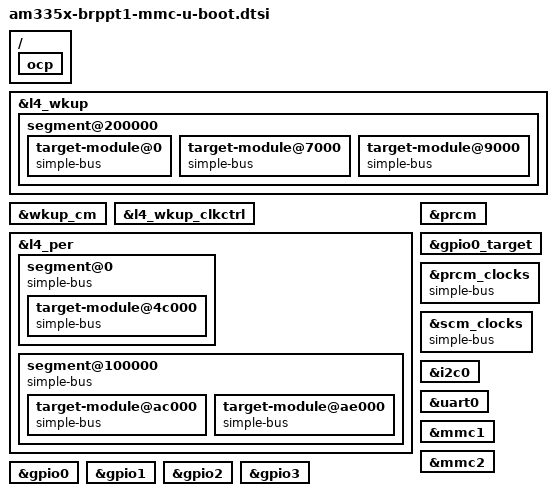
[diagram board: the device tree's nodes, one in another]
// SPDX-License-Identifier: GPL-2.0+
/*
 * Copyright (C) 2022 B&R Industrial Automation GmbH -
 * https://www.br-automation.com/
 */

/ {
	ocp {
		u-boot,dm-all;
	};
};

&l4_wkup {
	u-boot,dm-all;
	segment@200000 {
		u-boot,dm-all;
		target-module@0
		{
			u-boot,dm-all;
			compatible = "simple-bus";
		};
		target-module@7000 {
			u-boot,dm-all;
			compatible = "simple-bus";
		};
		target-module@9000 {
			u-boot,dm-all;
			compatible = "simple-bus";
		};
	};
};

&wkup_cm {
	u-boot,dm-all;
};

&l4_wkup_clkctrl {
	u-boot,dm-all;
};

&l4_per {
	u-boot,dm-all;
	segment@0 {
		u-boot,dm-all;
		compatible = "simple-bus";
		target-module@4c000 {
			u-boot,dm-all;
			compatible = "simple-bus";
		};
	};

	segment@100000 {
		u-boot,dm-all;
		compatible = "simple-bus";
		target-module@ac000 {
			u-boot,dm-all;
			compatible = "simple-bus";
		};
		target-module@ae000 {
			u-boot,dm-all;
			compatible = "simple-bus";
		};
	};
};

&prcm {
	u-boot,dm-all;
};

&gpio0_target {
	u-boot,dm-all;
};

&prcm_clocks {
	compatible = "simple-bus";
};

&scm_clocks {
	compatible = "simple-bus";
};

&i2c0 {
	u-boot,dm-all;
};

&uart0 {
	u-boot,dm-all;
};

&mmc1 {
	u-boot,dm-all;
};

&mmc2 {
	u-boot,dm-all;
};

&gpio0 {
	u-boot,dm-all;
};

&gpio1 {
	u-boot,dm-all;
};

&gpio2 {
	u-boot,dm-all;
};

&gpio3 {
	u-boot,dm-all;
};
